# ipro6s register map
Vendor: intelpro; Series: IPRO6S
CPU: ipro6s, little endian
Registers are 32-bit, read-write, reset 0x0 unless marked. A register's access mark holds for its fields unless they carry their own. Offsets are from the block's base; [hi:lo] are bit positions; {n}, {i} and the like mark numbered series.

## AON
Base 0x3008F000
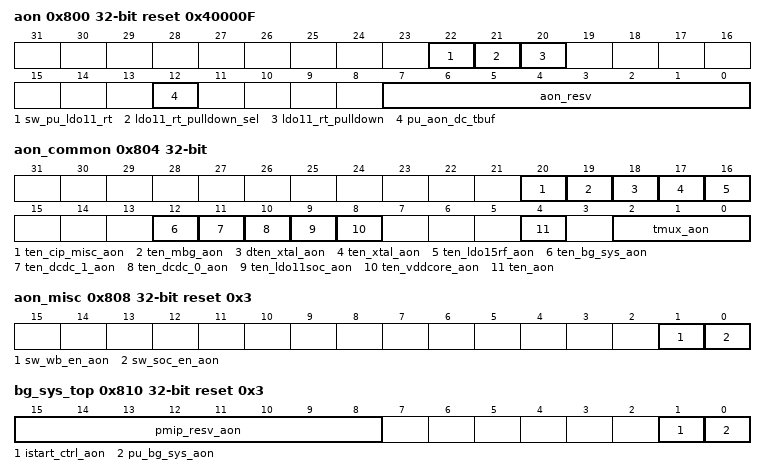
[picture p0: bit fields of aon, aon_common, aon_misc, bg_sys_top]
0x800 aon reset 0x40000F
  [22] sw_pu_ldo11_rt
  [21] ldo11_rt_pulldown_sel — 0: hardware control pulldown when pu_ldo11rt=0, 1: register control
  [20] ldo11_rt_pulldown — 1: pulldown
  [12] pu_aon_dc_tbuf
  [7:0] aon_resv — [0]xtal32k_dtest_pd
0x804 aon_common
  [20] ten_cip_misc_aon
  [19] ten_mbg_aon
  [18] dten_xtal_aon
  [17] ten_xtal_aon
  [16] ten_ldo15rf_aon
  [12] ten_bg_sys_aon
  [11] ten_dcdc_1_aon — dc test1
  [10] ten_dcdc_0_aon — dc test0
  [9] ten_ldo11soc_aon
  [8] ten_vddcore_aon
  [4] ten_aon
  [2:0] tmux_aon
0x808 aon_misc reset 0x3
  [1] sw_wb_en_aon, [0] sw_soc_en_aon
0x810 bg_sys_top reset 0x3
  [15:8] pmip_resv_aon
  [1] istart_ctrl_aon — bg_sys start-up circuit control 1: when avdd33>2.3V, 0: when avdd33<=2.3V
  [0] pu_bg_sys_aon
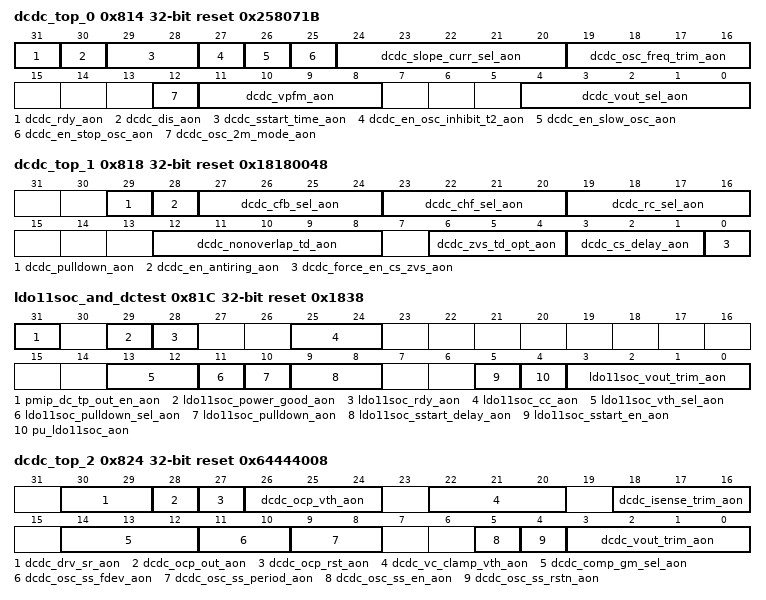
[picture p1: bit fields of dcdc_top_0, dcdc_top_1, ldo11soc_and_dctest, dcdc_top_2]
0x814 dcdc_top_0 reset 0x258071B (reset mask 0x7FFF1F1F)
  [31] dcdc_rdy_aon ro
  [30] dcdc_dis_aon — 1: disable dcdc function, for DCDC bypass mode
  [29:28] dcdc_sstart_time_aon — soft start time option
  [27] dcdc_en_osc_inhibit_t2_aon — inhibit t2 of osc
  [26] dcdc_en_slow_osc_aon — slow osc
  [25] dcdc_en_stop_osc_aon — stop osc
  [24:20] dcdc_slope_curr_sel_aon — current selection for slope compensation 5: if inductor value=2.2uH 9: if inductor value=1uH 2: if inductor value=4.7uH
  [19:16] dcdc_osc_freq_trim_aon — osc frequency trimming bits
  [12] dcdc_osc_2m_mode_aon — osc frequency selection, default 1MHz
  [11:8] dcdc_vpfm_aon — pfm mode threshold
  [4:0] dcdc_vout_sel_aon — output voltage sel: 0: 1.125V, 1: 1.15V, 15: 1.5V, 27: 1.8V, 31: 1.9V
0x818 dcdc_top_1 reset 0x18180048
  [29] dcdc_pulldown_aon — output pulldown option 0: floating output when disable 1: pulldown output to ground when disable
  [28] dcdc_en_antiring_aon — antiring enable
  [27:24] dcdc_cfb_sel_aon — compensation cfb selection
  [23:20] dcdc_chf_sel_aon — compensation chf selection
  [19:16] dcdc_rc_sel_aon — compensation rc selection
  [12:8] dcdc_nonoverlap_td_aon — nonoverlap clock delay option
  [6:4] dcdc_zvs_td_opt_aon — zvs circuits enable delay option
  [3:1] dcdc_cs_delay_aon — cs circuits enable delay option
  [0] dcdc_force_en_cs_zvs_aon — force cs and zvs circuits enablable
0x81C ldo11soc_and_dctest reset 0x1838 (reset mask 0x83003F3F)
  [31] pmip_dc_tp_out_en_aon — pmip dc test output enable
  [29] ldo11soc_power_good_aon ro
  [28] ldo11soc_rdy_aon ro
  [25:24] ldo11soc_cc_aon — ldo11soc compensation capacitor option
  [13:12] ldo11soc_vth_sel_aon — vdd11soc pwr_ok detection threshold selection
  [11] ldo11soc_pulldown_sel_aon — ldo11 output pulldown signal selection 0: vout pulldown controlled by pd signal 1: vout pulldown controlled by pulldown signal
  [10] ldo11soc_pulldown_aon — vout pulldown signal 0: floating output 1: pulldown output to ground
  [9:8] ldo11soc_sstart_delay_aon — soft start delay time option
  [5] ldo11soc_sstart_en_aon — ldo11 soft start select option 0: no soft start 1: with soft start function
  [4] pu_ldo11soc_aon — power up ldo11soc
  [3:0] ldo11soc_vout_trim_aon — output voltage trim: 0: 92%, 7: 99%, 8: 100%, 9: 101%, f: 107%
0x820 psw_irrcv
  [0] pu_ir_psw_aon — power up ir rx switch
0x824 dcdc_top_2 reset 0x64444008 (reset mask 0x6F777F3F)
  [30:29] dcdc_drv_sr_aon — powerMOS driver slew rate selection: 0: SR *1, 1: SR *2, 2: SR *4, 3: SR *40
  [28] dcdc_ocp_out_aon ro — ocp latched output
  [27] dcdc_ocp_rst_aon — reset dcdc_ocp_out_aon latch
  [26:24] dcdc_ocp_vth_aon — ocp threshold voltage
  [22:20] dcdc_vc_clamp_vth_aon — vc clamp threshold voltage
  [18:16] dcdc_isense_trim_aon — current sense R tuning
  [14:12] dcdc_comp_gm_sel_aon — compensator OTA gm tuning
  [11:10] dcdc_osc_ss_fdev_aon — osc spread spectrum frequency deviation
  [9:8] dcdc_osc_ss_period_aon — osc spread spectrum period
  [5] dcdc_osc_ss_en_aon — osc spread spectrum enable
  [4] dcdc_osc_ss_rstn_aon
  [3:0] dcdc_vout_trim_aon — output voltage trim 0: 93%, 1: 94%, 7: 100%, 8: 101%, 15: 108%
0x828 vddcore_psw reset not defined
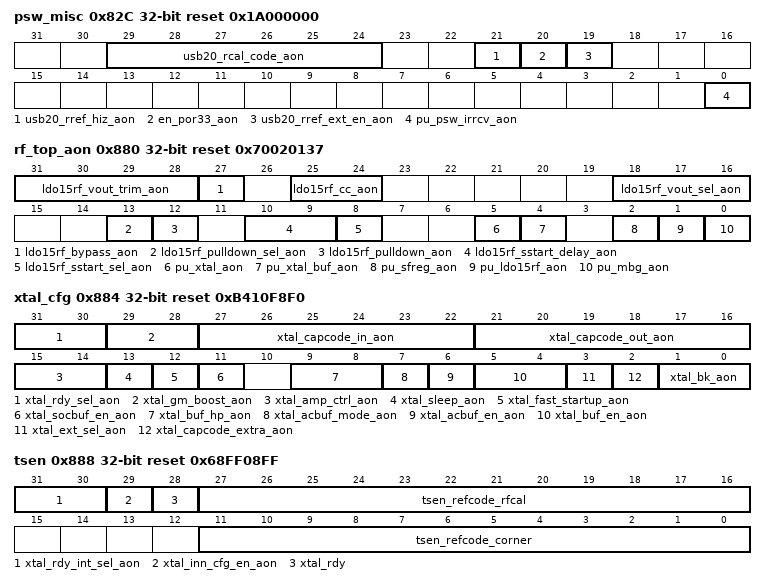
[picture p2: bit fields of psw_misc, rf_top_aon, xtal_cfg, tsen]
0x82C psw_misc reset 0x1A000000
  [29:24] usb20_rcal_code_aon — trim the internal resistor for RREF, default 12k Ohm
  [21] usb20_rref_hiz_aon — 0: use internal resistor for RREF; 1: disable internal resistor for RREF
  [20] en_por33_aon — enable efuse_psw
  [19] usb20_rref_ext_en_aon — enable extenal resistor for RREF through GPIO
  [0] pu_psw_irrcv_aon — power up ir rx switch
0x880 rf_top_aon reset 0x70020137
  [31:28] ldo15rf_vout_trim_aon — output voltage trim 0: 93%, 1: 94%, 7: 100%, 8: 101%, 15: 108%
  [27] ldo15rf_bypass_aon
  [25:24] ldo15rf_cc_aon — compensation capacitor option
  [18:16] ldo15rf_vout_sel_aon — 0: 1.4V, 1: 1.45V, 2: 1.5V, 3: 1.55V, 4: 1.6V, 5: 1.65V, 6: 1.7V, 7: 1.8V
  [13] ldo15rf_pulldown_sel_aon — output pulldown signal selection 0: vout pulldown controlled by pd signal 1: vout pulldown controlled by pulldown signal
  [12] ldo15rf_pulldown_aon — vout pulldown signal 0: floating output 1: pulldown output to ground
  [10:9] ldo15rf_sstart_delay_aon — soft start delay time option
  [8] ldo15rf_sstart_sel_aon — ldo11 soft start select option 0: no soft start 1: with soft start function
  [5] pu_xtal_aon — power up xtal
  [4] pu_xtal_buf_aon — power up buffer in xtal
  [2] pu_sfreg_aon
  [1] pu_ldo15rf_aon
  [0] pu_mbg_aon
0x884 xtal_cfg reset 0xB410F8F0
  [31:30] xtal_rdy_sel_aon — 0:128us, 1:256us, 2:512us, 3:1ms
  [29:28] xtal_gm_boost_aon — 1: larger negative gm in xtal
  [27:22] xtal_capcode_in_aon — capcode for xtal at xtal_in node (also copy from efuse)
  [21:16] xtal_capcode_out_aon — capcode for xtal at xtal_out node (also copy from efuse)
  [15:14] xtal_amp_ctrl_aon — 11: large oscillation amplitude 00: small oscillation amplitude
  [13] xtal_sleep_aon — set 38.4M xtal in sleep mode
  [12] xtal_fast_startup_aon — speed up startup procedure
  [11] xtal_socbuf_en_aon
  [9:8] xtal_buf_hp_aon — set xtal buffer to high performance mode
  [7] xtal_acbuf_mode_aon
  [6] xtal_acbuf_en_aon
  [5:4] xtal_buf_en_aon — enable xtal output buffer
  [3] xtal_ext_sel_aon — use offchip clock (There are force to Zero bit for FT in CCI register)
  [2] xtal_capcode_extra_aon — Extra capacitor for supporting 15pF loading (also copy from efuse)
  [1:0] xtal_bk_aon — reseved for xtal
0x888 tsen reset 0x68FF08FF (reset mask 0xEFFF0FFF)
  [31:30] xtal_rdy_int_sel_aon — 0:4096*Txtal ~~~ 3:32768*Txtal, fast startup config time window
  [29] xtal_inn_cfg_en_aon — enable internal configuration for fast startup
  [28] xtal_rdy ro — xtal ready signal for soc clock used (rf performance not be gaurantee at this time shot)
  [27:16] tsen_refcode_rfcal — record temperature sensor reference code at RF_calibration
  [11:0] tsen_refcode_corner — record temperature sensor reference code at ATE for self corner calibration (also copy from efuse)
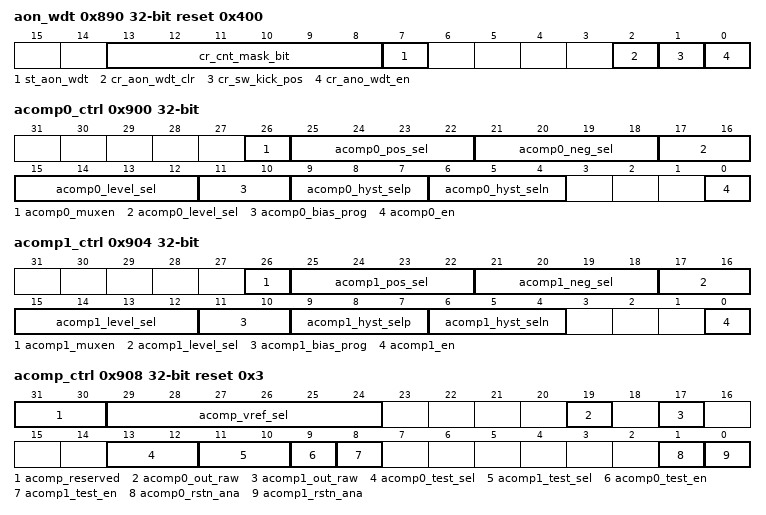
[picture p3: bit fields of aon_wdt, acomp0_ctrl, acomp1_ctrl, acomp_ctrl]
0x890 aon_wdt reset 0x400 (reset mask 0x3F07)
  [13:8] cr_cnt_mask_bit — Aon watch dog timer mask bit
  [7] st_aon_wdt ro — Aon watch dog timer reset status
  [2] cr_aon_wdt_clr wo — Aon watch dog timer reset status clear
  [1] cr_sw_kick_pos wo — Aon watch dog timer sw kick
  [0] cr_ano_wdt_en — Aon watch dog timer enable
0x900 acomp0_ctrl
  [26] acomp0_muxen — ACOMP0 input MUX enable bit. This bit should be asserted earlier than 'en' bit. 1'h0 disable input mux 1'h1 enable input mux
  [25:22] acomp0_pos_sel — ACOMP0 positive input select bits. 1'h0 acomp_ch<0> 1'h1 acomp_ch<1> 0x2 acomp_ch<2> 0x3 acomp_ch<3> 0x4 acomp_ch<4> 0x5 acomp_ch<5> 0x6 acomp_ch<6> 0x7 acomp_ch<7> 0x8 daca 0x9 dacb 0xA vref_bg_1p25 0xB Vbat*vref_sel 0xC Vbat*vref_sel 0xD Vbat*vref_sel 0xE Vbat*vref_sel 0xF vssa
  [21:18] acomp0_neg_sel — ACOMP0 negative input select bits. 1'h0 acomp_ch<0> 1'h1 acomp_ch<1> 0x2 acomp_ch<2> 0x3 acomp_ch<3> 0x4 acomp_ch<4> 0x5 acomp_ch<5> 0x6 acomp_ch<6> 0x7 acomp_ch<7> 0x8 daca 0x9 dacb 0xA vref_bg_1p25 0xB Vbat*vref_sel 0xC Vbat*vref_sel 0xD Vbat*vref_sel 0xE Vbat*vref_sel 0xF vssa
  [17:12] acomp0_level_sel — Scaling factor select bits for VIO reference level. 1'h0X Scaling factor=0.25 1'h1X Scaling factor= 0.5 0x2X Scaling factor= 0.75 0x3X Scaling factor= 1 others reserved.
  [11:10] acomp0_bias_prog — ACOMP0 bias current control bits or response time control bits. 1'h0 power mode1 (slow response mode) 1'h1 power mode2 (medium response mode) 0x2 power mode3 (fast response mode) 0x3 Reserved
  [9:7] acomp0_hyst_selp — Select ACOMP0 positive hysteresis voltage level. 1'h0 No hysteresis 1'h1 +10 mV hysteresis 0x2 +20 mV hysteresis 0x3 +30 mV hysteresis 0x4 +40 mV hysteresis 0x5 +50 mV hysteresis 0x6 +60 mV hysteresis 0x7 +70 mV hysteresis
  [6:4] acomp0_hyst_seln — Select ACOMP0 negative hysteresis voltage level. 1'h0 No hysteresis 1'h1 -10 mV hysteresis 0x2 -20 mV hysteresis 0x3 -30 mV hysteresis 0x4 -40 mV hysteresis 0x5 -50 mV hysteresis 0x6 -60 mV hysteresis 0x7 -70 mV hysteresis
  [0] acomp0_en — ACOMP0 enable 1'h0 disable 1'h1 enable
0x904 acomp1_ctrl
  [26] acomp1_muxen — ACOMP1 input MUX enable bit. This bit should be asserted earlier than 'en' bit. 1'h0 disable input mux 1'h1 enable input mux
  [25:22] acomp1_pos_sel — ACOMP1 positive input select bits. 1'h0 acomp_ch<0> 1'h1 acomp_ch<1> 0x2 acomp_ch<2> 0x3 acomp_ch<3> 0x4 acomp_ch<4> 0x5 acomp_ch<5> 0x6 acomp_ch<6> 0x7 acomp_ch<7> 0x8 daca 0x9 dacb 0xA vref_bg_1p25 0xB Vbat*vref_sel 0xC Vbat*vref_sel 0xD Vbat*vref_sel 0xE Vbat*vref_sel 0xF vssa
  [21:18] acomp1_neg_sel — ACOMP1 negative input select bits. 1'h0 acomp_ch<0> 1'h1 acomp_ch<1> 0x2 acomp_ch<2> 0x3 acomp_ch<3> 0x4 acomp_ch<4> 0x5 acomp_ch<5> 0x6 acomp_ch<6> 0x7 acomp_ch<7> 0x8 daca 0x9 dacb 0xA vref_bg_1p25 0xB Vbat*vref_sel 0xC Vbat*vref_sel 0xD Vbat*vref_sel 0xE Vbat*vref_sel 0xF vssa
  [17:12] acomp1_level_sel — Scaling factor select bits for VIO reference level. 1'h0X Scaling factor=0.25 1'h1X Scaling factor= 0.5 0x2X Scaling factor= 0.75 0x3X Scaling factor= 1 others reserved.
  [11:10] acomp1_bias_prog — ACOMP1 bias current control bits or response time control bits. 1'h0 power mode1 (slow response mode) 1'h1 power mode2 (medium response mode) 0x2 power mode3 (fast response mode) 0x3 Reserved
  [9:7] acomp1_hyst_selp — Select ACOMP1 positive hysteresis voltage level. 1'h0 No hysteresis 1'h1 +10 mV hysteresis 0x2 +20 mV hysteresis 0x3 +30 mV hysteresis 0x4 +40 mV hysteresis 0x5 +50 mV hysteresis 0x6 +60 mV hysteresis 0x7 +70 mV hysteresis
  [6:4] acomp1_hyst_seln — Select ACOMP1 negative hysteresis voltage level. 1'h0 No hysteresis 1'h1 -10 mV hysteresis 0x2 -20 mV hysteresis 0x3 -30 mV hysteresis 0x4 -40 mV hysteresis 0x5 -50 mV hysteresis 0x6 -60 mV hysteresis 0x7 -70 mV hysteresis
  [0] acomp1_en — ACOMP1 enable 1'h0 disable 1'h1 enable
0x908 acomp_ctrl reset 0x3 (reset mask 0xFF003F03)
  [31:30] acomp_reserved
  [29:24] acomp_vref_sel — 6'h0: 1/66*avdd33 6'h1: 2/66*avdd33 … … 6'h62: 63/66*avdd33 6'h63: 64/66*avdd33
  [19] acomp0_out_raw ro — ACOMP0 comparison output value.
  [17] acomp1_out_raw ro — ACOMP1 comparison output value.
  [13:12] acomp0_test_sel — sweep 0~3 test points
  [11:10] acomp1_test_sel — sweep 0~3 test points
  [9] acomp0_test_en — Test enable 1'h0 analog test disabled (ATEST is set in Hi-Z state) 1'h1 analog test point enabled to ATEST
  [8] acomp1_test_en — Test enable 1'h0 analog test disabled (ATEST is set in Hi-Z state) 1'h1 analog test point enabled to ATEST
  [1] acomp0_rstn_ana — Soft reset for DAC channel B, active low
  [0] acomp1_rstn_ana — Soft reset for DAC channel A, active low
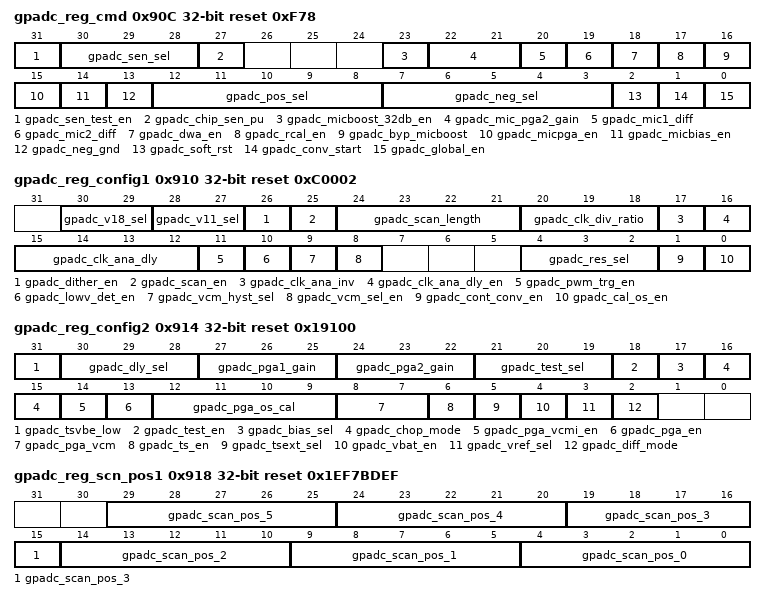
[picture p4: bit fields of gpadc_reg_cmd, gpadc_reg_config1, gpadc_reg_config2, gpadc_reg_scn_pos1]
0x90C gpadc_reg_cmd reset 0xF78
  [31] gpadc_sen_test_en — enable sensor dc test mux
  [30:28] gpadc_sen_sel — selected output current channel and measurement channel 2'h0: 1st channel 2'h1: 2nd channel 2'h2: 3rd channel 2'h3: 4th channel
  [27] gpadc_chip_sen_pu — enable chip sensor test 1'b0: disable 1'b1: enable
  [23] gpadc_micboost_32db_en — micboost 32db enable 1'b0: 16dB 1'b1: 32dB
  [22:21] gpadc_mic_pga2_gain — mic_pga2_gain 2'h0: 0dB 2'h1: 6dB 2'h2: -6dB 2'h3: 12dB
  [20] gpadc_mic1_diff — mic1 diff enable 1'b0: single 1'b1: diff
  [19] gpadc_mic2_diff — mic2 diff enable 1'b0: single 1'b1: diff
  [18] gpadc_dwa_en — dwa enable 1'b0: dwa disable 1'b1: dwa enable
  [17] gpadc_rcal_en — rcal enable 1'b0: rcal disable 1'b1: rcal enable
  [16] gpadc_byp_micboost — micboost amp bypass 1'b0: not bypass 1'b1: bypass
  [15] gpadc_micpga_en — micpga enable 1'b0: micpga disable 1'b1: miapga enable
  [14] gpadc_micbias_en — enable micbias 1'b0: micbias power down 1'b1: miabias power on
  [13] gpadc_neg_gnd — set negative input of adc to ground 1'b0: disable 1'b1: enable
  [12:8] gpadc_pos_sel — select adc positive input in none-scan mode 5‘h0 gpio0 5'h1 gpio1 5'h2 gpio2 5‘h3 gpio3 5'h4 gpio4 5'h5 gpio5 5‘h6 gpio6 5'h7 gpio7 5'h8 gpio8 5‘h9 gpio9 5'h10 gpio10 5'h11 gpio11 5‘h12 daca 5'h13 dacb 5'h14 temp_p 5‘h15 temp_n 5'h16 vref 5'h17 atest 5‘h18 vbat/2 5'h19 vp3_diode 5'h20 vp2_diode 5‘h21 vp1_diode 5'h22 vp0_diode 5'h23~31 avss
  [7:3] gpadc_neg_sel — select adc negative input in none-scan mode 5‘h0 gpio0 5'h1 gpio1 5'h2 gpio2 5‘h3 gpio3 5'h4 gpio4 5'h5 gpio5 5‘h6 gpio6 5'h7 gpio7 5'h8 gpio8 5‘h9 gpio9 5'h10 gpio10 5'h11 gpio11 5‘h12 daca 5'h13 dacb 5'h14 temp_p 5‘h15 temp_n 5'h16 vref 5'h17 atest 5‘h18 vbat/2 5'h19 vn3_diode 5'h20 vn2_diode 5‘h21 vn1_diode 5'h22 vn0_diode 5'h23~31 avss
  [2] gpadc_soft_rst — user reset the whole block 1'h0: not reset 1'h1: reset
  [1] gpadc_conv_start — 1'h0: stop converation 1'h1: start converation
  [0] gpadc_global_en — 1'h0: disable ADC 1'h1: enable ADC
0x910 gpadc_reg_config1 reset 0xC0002
  [30:29] gpadc_v18_sel — internal vdd18 select
  [28:27] gpadc_v11_sel — internal vdd11 select
  [26] gpadc_dither_en — Dither compensation enable
  [25] gpadc_scan_en — select scan mode enable: 0: select gpadc_pos/neg_sel;1: select : select gpadc_scan_pos_x and gpadc_scan_neg_x
  [24:21] gpadc_scan_length — select scan mode length 4'b0000 : select gpadc_scan_pos_0 and gpadc_scan_neg_0 4'b0001 : select gpadc_scan_pos_1 and gpadc_scan_neg_1 4'b0010 : select gpadc_scan_pos_2 and gpadc_scan_neg_2 4'b0011 : select gpadc_scan_pos_3 and gpadc_scan_neg_3 4'b0100 : select gpadc_scan_pos_4 and gpadc_scan_neg_4 4'b0101 : select gpadc_scan_pos_5 and gpadc_scan_neg_5 4'b0110 : select gpadc_scan_pos_6 and gpadc_scan_neg_6 4'b0111 : select gpadc_scan_pos_7 and gpadc_scan_neg_7 4'b1000 : select gpadc_scan_pos_8 and gpadc_scan_neg_8 4'b1001 : select gpadc_scan_pos_9 and gpadc_scan_neg_9 4'b1010 : select gpadc_scan_pos_10 and gpadc_scan_neg_10 4'b1011 : select gpadc_scan_pos_11 and gpadc_scan_neg_11
  [20:18] gpadc_clk_div_ratio — analog 32M clock division ratio 3'b000: div=1 3'b001: div=4 3'b010: div=8 3'b011: div=12 3'b100: div=16 3'b101: div=20 3'b110: div=24 3'b111: div=32
  [17] gpadc_clk_ana_inv — analog clock 2M inverted
  [16] gpadc_clk_ana_dly_en — analog clock 2M delay enable
  [15:12] gpadc_clk_ana_dly — analog clock 2M delay cycle count
  [11] gpadc_pwm_trg_en — Enable signal for PWM to trigger ADC sampling
  [10] gpadc_lowv_det_en — Low power supply detected enable
  [9] gpadc_vcm_hyst_sel — pga vcm hystersis select when vcm_sel_en is enabled
  [8] gpadc_vcm_sel_en — pga vcm selected when lowv_det_en is enable
  [4:2] gpadc_res_sel — adc resolution/over-sample rate select 3'b000 12bit 2MS/s, OSR=1 3'b001 14bit 125kS/s, OSR=16 3'b010 14bit 31.25kS/s, OSR=64 3'b011 16bit 15.625KS/s, OSR=128 (voice mode16KS/s) 3'b100 16bit 7.8125KS/s, OSR=256 (voice mode 8KS/s)
  [1] gpadc_cont_conv_en — To enable continuous conversion 1'h0: one shot conversion 1'h1: continuous conversion
  [0] gpadc_cal_os_en — offset calibration enable
0x914 gpadc_reg_config2 reset 0x19100
  [31] gpadc_tsvbe_low — tsen diode current
  [30:28] gpadc_dly_sel — adc conversion speed
  [27:25] gpadc_pga1_gain — 3'h0: disable 3'h1: gain=1 3'h2: gain=2 3'h3: gain=4 3'h4: gain=8 3'h5: gain=16 3'h6: gain=32 3'h7: gain=32
  [24:22] gpadc_pga2_gain — 3'h0: disable 3'h1: gain=1 3'h2: gain=2 3'h3: gain=4 3'h4: gain=8 3'h5: gain=16 3'h6: gain=32 3'h7: gain=32
  [21:19] gpadc_test_sel — select test point 0~7
  [18] gpadc_test_en — Analog test enable.
  [17] gpadc_bias_sel — adc analog portion low power mode select 1'h0: bandgap system 1'h1:aon bandgap
  [16:15] gpadc_chop_mode — 2'b11 all off 2'b11 Vref AZ on 2'b11 Vref AZ and PGA chop on 2'b11 Vref AZ and PGA chop+RPC on
  [14] gpadc_pga_vcmi_en — enable pga input vcm bias
  [13] gpadc_pga_en — 1'h0: disable PGA 1'h1 enable PGA
  [12:9] gpadc_pga_os_cal — pga offset calibration
  [8:7] gpadc_pga_vcm — Audio PGA output common mode control 2'b00: cm=1.3V 2'b11: cm=1.4V 2'b11: cm=1.5V 2'b11: cm=1.6V
  [6] gpadc_ts_en — 1'h0: disable temperature sensor 1'h1: enable temperature sensor
  [5] gpadc_tsext_sel — 1'h0: internal diode mode 1'h1: external diode mode
  [4] gpadc_vbat_en — 1'h0: disable VBAT sensor 1'h1 enable VBAT sensor
  [3] gpadc_vref_sel — ADC reference select 1'h0 3.2V 1'h1 2.0V
  [2] gpadc_diff_mode — 1'h0 single-ended 1'h1 differential
0x918 gpadc_reg_scn_pos1 reset 0x1EF7BDEF — adc converation sequence 1
  [5n+4:5n] gpadc_scan_pos_{n} (n=0..5) — definition is the same as adc_reg_cmd.adc_pos_sel
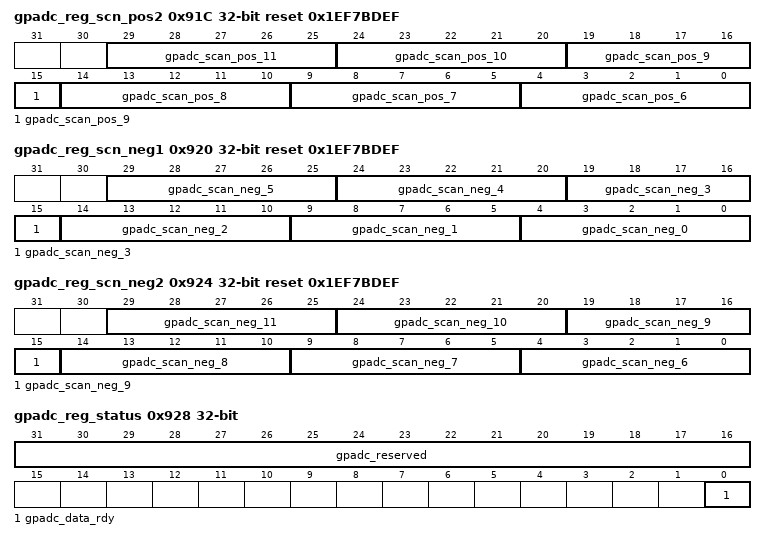
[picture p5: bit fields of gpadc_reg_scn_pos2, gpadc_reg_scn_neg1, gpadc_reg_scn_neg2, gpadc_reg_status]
0x91C gpadc_reg_scn_pos2 reset 0x1EF7BDEF — adc converation sequence 2
  [5n-26:5n-30] gpadc_scan_pos_{n} (n=6..11) — definition is the same as adc_reg_cmd.adc_pos_sel
0x920 gpadc_reg_scn_neg1 reset 0x1EF7BDEF — adc converation sequence 3
  [5n+4:5n] gpadc_scan_neg_{n} (n=0..5) — definition is the same as adc_reg_cmd.adc_neg_sel
0x924 gpadc_reg_scn_neg2 reset 0x1EF7BDEF — adc converation sequence 4
  [5n-26:5n-30] gpadc_scan_neg_{n} (n=6..11) — definition is the same as adc_reg_cmd.adc_neg_sel
0x928 gpadc_reg_status (reset mask 0xFFFF0000)
  [31:16] gpadc_reserved
  [0] gpadc_data_rdy ro — ADC final conversion data ready
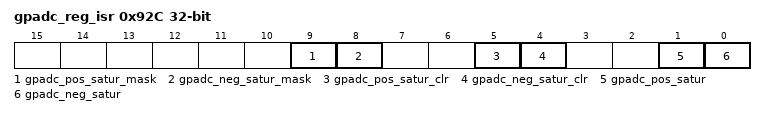
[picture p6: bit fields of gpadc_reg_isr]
0x92C gpadc_reg_isr (reset mask 0x330)
  [9] gpadc_pos_satur_mask — write 1 mask
  [8] gpadc_neg_satur_mask — write 1 mask
  [5] gpadc_pos_satur_clr — Write 1 to clear flag
  [4] gpadc_neg_satur_clr — Write 1 to clear flag
  [1] gpadc_pos_satur ro — ADC data positive side saturation interrupt flag
  [0] gpadc_neg_satur ro — ADC data negative side saturation interrupt flag
0x930 gpadc_reg_result reset not defined
  [25:0] gpadc_data_out ro — ADC finial conversion result data, after calibration and signed/unsigned process
0x934 gpadc_reg_raw_result reset not defined
  [11:0] gpadc_raw_data ro — ADC Raw data
0x938 gpadc_reg_define
  [15:0] gpadc_os_cal_data — User defined or self calculated offset data 16-bit signed
0x93C hbncore_resv0
  [31:0] hbncore_resv0_data
0x940 hbncore_resv1 reset 0xFFFFFFFF
  [31:0] hbncore_resv1_data
